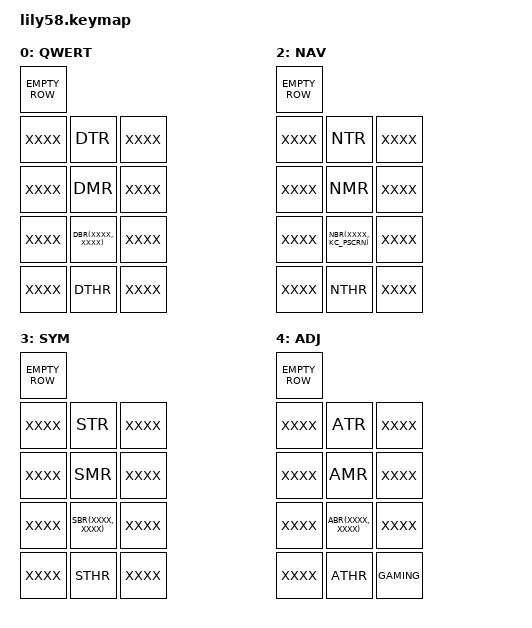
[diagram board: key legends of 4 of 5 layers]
#include <behaviors.dtsi>

#include "base.keymap"

#define EMPTY_ROW XXXX XXXX XXXX XXXX XXXX XXXX  XXXX XXXX XXXX XXXX XXXX XXXX

#define NUMLOCKED(NUM) \
  ZMK_MACRO(numlocked_##NUM, \
    wait-ms = <10>; \
    bindings \
        = <&macro_tap KC_NLCK> \
        , <&macro_press &kp KP_N##NUM> \
        , <&macro_tap KC_NLCK> \
        , <&macro_release &kp KP_N##NUM>; \
  )

/ {  
  combos {
    compatible = "zmk,combos";
    COMBO(numlocked_1, <1 43>, _GAMING, &numlocked_1)
    COMBO(numlocked_2, <2 43>, _GAMING, &numlocked_2)
    COMBO(numlocked_3, <3 43>, _GAMING, &numlocked_3)
    COMBO(numlocked_4, <4 43>, _GAMING, &numlocked_4)
  };

  macros {
    NUMLOCKED(1)
    NUMLOCKED(2)
    NUMLOCKED(3)
    NUMLOCKED(4)
  };

  keymap {
    compatible = "zmk,keymap";
    default_layer {
      display-name = "QWERT";
      bindings = <
        EMPTY_ROW
        XXXX DTR XXXX
        XXXX DMR XXXX
        XXXX DBR(XXXX, XXXX) XXXX
        XXXX DTHR XXXX
      >;
    };

    gaming_layer {
      display-name = "GAME";
      bindings = <
//,-----------------------------------------------------.                    ,-----------------------------------------------------.
   KC_ESC   KC_N1    KC_N2    KC_N3    KC_N4    KC_N5                         KC_N6    KC_N7    KC_N8    KC_N9    KC_N0    KC_BSPC
//|--------+--------+--------+--------+--------+--------|                    |--------+--------+--------+--------+--------+--------|
   KC_LCTRL KC_Q     KC_W     KC_E     KC_R     KC_T                          KC_Y     KC_U     KC_I     KC_O     KC_P     KC_RCTRL
//|--------+--------+--------+--------+--------+--------|                    |--------+--------+--------+--------+--------+--------|
   KC_LSHFT KC_A     KC_S     KC_D     KC_F     KC_G                          KC_H     KC_J     KC_K     KC_L     KC_SEMI  KC_RSHFT
//|--------+--------+--------+--------+--------+--------+--------|  |--------+--------+--------+--------+--------+--------+--------|
   KC_LGUI  KC_Z     KC_X     KC_C     KC_V     KC_B     KC_M        KC_NLCK  KC_N     KC_M     KC_COMMA KC_DOT   KC_FSLH  KC_RGUI
//|--------+--------+--------+--------+--------+--------+--------|  |--------+--------+--------+--------+--------+--------+--------|
                              NAV      KC_TAB   KC_LALT  KC_SPACE    KC_RET   SYM_TAB  XXXX     XXXX
//                           `-----------------------------------'  `-----------------------------------'
      >;
    };
        
    num_nav_layer {
      display-name = "NAV";
      bindings = <
        EMPTY_ROW
        XXXX NTR XXXX
        XXXX NMR XXXX
        XXXX NBR(XXXX, KC_PSCRN) XXXX
        XXXX NTHR XXXX
      >;
    };

    symbol_layer {
      display-name = "SYM";
      bindings = <
        EMPTY_ROW
        XXXX STR XXXX
        XXXX SMR XXXX
        XXXX SBR(XXXX, XXXX) XXXX
        XXXX STHR XXXX
      >;
    };
        
    adjust_layer {
      display-name = "ADJ";
      bindings = <
        EMPTY_ROW
        XXXX ATR XXXX
        XXXX AMR XXXX
        XXXX ABR(XXXX, XXXX) XXXX
        XXXX ATHR GAMING
      >;
    };
  }; 
};
